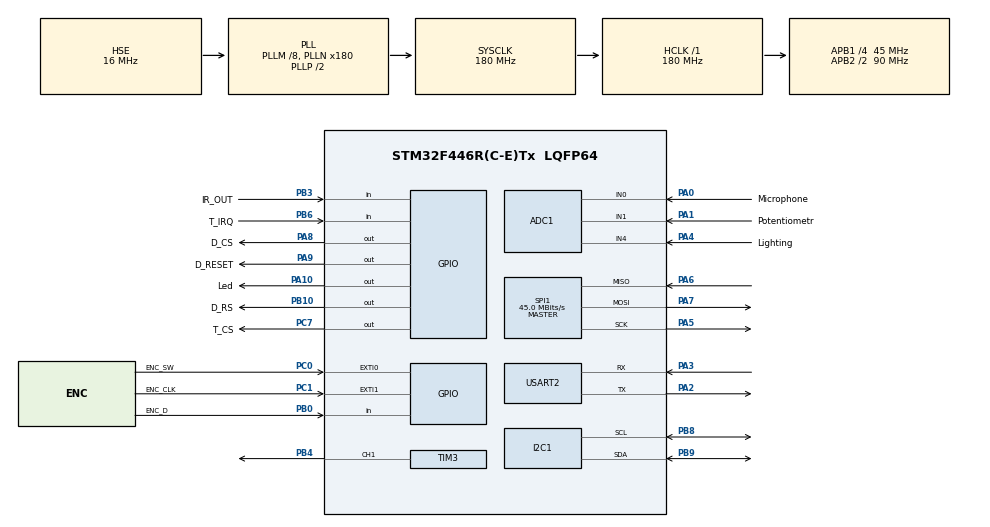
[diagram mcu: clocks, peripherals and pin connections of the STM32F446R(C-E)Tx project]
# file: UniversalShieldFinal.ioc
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ADC1.Channel-0\#ChannelRegularConversion=ADC_CHANNEL_0
ADC1.NbrOfConversionFlag=1
ADC1.Rank-0\#ChannelRegularConversion=1
ADC1.SamplingTime-0\#ChannelRegularConversion=ADC_SAMPLETIME_3CYCLES
ADC1.master=1
I2C1.I2C_Mode=I2C_Fast
Mcu.Family=STM32F4
Mcu.Name=STM32F446R(C-E)Tx
Mcu.Package=LQFP64
NVIC.EXTI0_IRQn=true\:15\:0\:true\:false\:true\:true\:true
NVIC.EXTI1_IRQn=true\:15\:0\:true\:false\:true\:true\:true
NVIC.PriorityGroup=NVIC_PRIORITYGROUP_4
PA0-WKUP.GPIO_Label=Microphone
PA0-WKUP.Signal=ADCx_IN0
PA1.GPIO_Label=Potentiometr
PA1.Signal=ADCx_IN1
PA10.GPIO_Label=Led
PA10.Signal=GPIO_Output
PA13.Mode=Serial_Wire
PA13.Signal=SYS_JTMS-SWDIO
PA14.Mode=Serial_Wire
PA14.Signal=SYS_JTCK-SWCLK
PA2.Mode=Asynchronous
PA2.Signal=USART2_TX
PA3.Mode=Asynchronous
PA3.Signal=USART2_RX
PA4.GPIO_Label=Lighting
PA4.Signal=ADCx_IN4
PA5.Mode=Full_Duplex_Master
PA5.Signal=SPI1_SCK
PA6.Mode=Full_Duplex_Master
PA6.Signal=SPI1_MISO
PA7.Mode=Full_Duplex_Master
PA7.Signal=SPI1_MOSI
PA8.GPIO_Label=D_CS
PA8.GPIO_Speed=GPIO_SPEED_FREQ_VERY_HIGH
PA8.PinState=GPIO_PIN_SET
PA8.Signal=GPIO_Output
PA9.GPIO_Label=D_RESET
PA9.GPIO_Speed=GPIO_SPEED_FREQ_VERY_HIGH
PA9.Signal=GPIO_Output
PB0.GPIO_Label=ENC_D
PB0.GPIO_PuPd=GPIO_PULLUP
PB0.Signal=GPIO_Input
PB10.GPIO_Label=D_RS
PB10.GPIO_Speed=GPIO_SPEED_FREQ_VERY_HIGH
PB10.Signal=GPIO_Output
PB3.GPIO_Label=IR_OUT
PB3.Signal=GPIO_Input
PB4.Signal=S_TIM3_CH1
PB6.GPIO_Label=T_IRQ
PB6.GPIO_PuPd=GPIO_PULLUP
PB6.Signal=GPIO_Input
PB8.Mode=I2C
PB8.Signal=I2C1_SCL
PB9.Mode=I2C
PB9.Signal=I2C1_SDA
PC0.GPIO_Label=ENC_SW
PC0.GPIO_ModeDefaultEXTI=GPIO_MODE_IT_FALLING
PC0.GPIO_PuPd=GPIO_PULLUP
PC0.Signal=GPXTI0
PC1.GPIO_Label=ENC_CLK
PC1.GPIO_ModeDefaultEXTI=GPIO_MODE_IT_FALLING
PC1.GPIO_PuPd=GPIO_PULLUP
PC1.Signal=GPXTI1
PC7.GPIO_Label=T_CS
PC7.GPIO_Speed=GPIO_SPEED_FREQ_VERY_HIGH
PC7.PinState=GPIO_PIN_SET
PC7.Signal=GPIO_Output
PH0-OSC_IN.Mode=HSE-External-Oscillator
PH0-OSC_IN.Signal=RCC_OSC_IN
PH1-OSC_OUT.Mode=HSE-External-Oscillator
PH1-OSC_OUT.Signal=RCC_OSC_OUT
ProjectManager.HeapSize=0x400
ProjectManager.StackSize=0x800
ProjectManager.TargetToolchain=STM32CubeIDE
RCC.AHBFreq_Value=180000000
RCC.APB1CLKDivider=RCC_HCLK_DIV4
RCC.APB1Freq_Value=45000000
RCC.APB1TimFreq_Value=90000000
RCC.APB2CLKDivider=RCC_HCLK_DIV2
RCC.APB2Freq_Value=90000000
RCC.APB2TimFreq_Value=180000000
RCC.CortexFreq_Value=180000000
RCC.HCLKFreq_Value=180000000
RCC.HSE_VALUE=16000000
RCC.PLLM=8
RCC.PLLN=180
RCC.PLLSourceVirtual=RCC_PLLSOURCE_HSE
RCC.SYSCLKFreq_VALUE=180000000
RCC.SYSCLKSource=RCC_SYSCLKSOURCE_PLLCLK
RCC.USBFreq_Value=180000000
RCC.VCOOutputFreq_Value=360000000
SH.ADCx_IN0.0=ADC1_IN0,IN0
SH.ADCx_IN1.0=ADC1_IN1,IN1
SH.ADCx_IN4.0=ADC1_IN4,IN4
SH.S_TIM3_CH1.0=TIM3_CH1,PWM Generation1 CH1
SPI1.CalculateBaudRate=45.0 MBits/s
SPI1.DataSize=SPI_DATASIZE_16BIT
SPI1.Direction=SPI_DIRECTION_2LINES
SPI1.Mode=SPI_MODE_MASTER
SPI1.VirtualType=VM_MASTER
TIM3.Channel-PWM\ Generation1\ CH1=TIM_CHANNEL_1
USART2.VirtualMode=VM_ASYNC
VP_TIM3_VS_ClockSourceINT.Mode=Internal
board=custom

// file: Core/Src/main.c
/* USER CODE BEGIN Header */
/**
  ******************************************************************************
  * @file           : main.c
  * @brief          : Main program body
  ******************************************************************************
  * @attention
  *
  * <h2><center>&copy; Copyright (c) 2020 STMicroelectronics.
  * All rights reserved.</center></h2>
  *
  * This software component is licensed by ST under BSD 3-Clause license,
  * the "License"; You may not use this file except in compliance with the
  * License. You may obtain a copy of the License at:
  *                        opensource.org/licenses/BSD-3-Clause
  *
  ******************************************************************************
  */
/* USER CODE END Header */

#include "main.h"
#include "adc.h"
#include "i2c.h"
#include "spi.h"
#include "tim.h"
#include "usart.h"
#include "gpio.h"

/* USER CODE BEGIN Includes */
#include "UniversalShield.h"
/* USER CODE END Includes */

void SystemClock_Config(void);

int main(void)
{

  /* MCU Configuration--------------------------------------------------------*/

  /* Reset of all peripherals, Initializes the Flash interface and the Systick. */
  HAL_Init();

  /* Configure the system clock */
  SystemClock_Config();

  /* Initialize all configured peripherals */
  MX_GPIO_Init();
  MX_ADC1_Init();
  MX_USART2_UART_Init();
  MX_I2C1_Init();
  MX_SPI1_Init();
  MX_TIM3_Init();
  /* USER CODE BEGIN 2 */
	//Вызов главной функции
	US_main();
  /* USER CODE END 2 */

  /* Infinite loop */
  while (1)
  {

  }
}

void SystemClock_Config(void)
{
  RCC_OscInitTypeDef RCC_OscInitStruct = {0};
  RCC_ClkInitTypeDef RCC_ClkInitStruct = {0};

  /** Configure the main internal regulator output voltage
  */
  __HAL_RCC_PWR_CLK_ENABLE();
  __HAL_PWR_VOLTAGESCALING_CONFIG(PWR_REGULATOR_VOLTAGE_SCALE1);
  /** Initializes the CPU, AHB and APB busses clocks
  */
  RCC_OscInitStruct.OscillatorType = RCC_OSCILLATORTYPE_HSE;
  RCC_OscInitStruct.HSEState = RCC_HSE_ON;
  RCC_OscInitStruct.PLL.PLLState = RCC_PLL_ON;
  RCC_OscInitStruct.PLL.PLLSource = RCC_PLLSOURCE_HSE;
  RCC_OscInitStruct.PLL.PLLM = 8;
  RCC_OscInitStruct.PLL.PLLN = 180;
  RCC_OscInitStruct.PLL.PLLP = RCC_PLLP_DIV2;
  RCC_OscInitStruct.PLL.PLLQ = 2;
  RCC_OscInitStruct.PLL.PLLR = 2;
  if (HAL_RCC_OscConfig(&RCC_OscInitStruct) != HAL_OK)
  {
    Error_Handler();
  }
  /** Activate the Over-Drive mode
  */
  if (HAL_PWREx_EnableOverDrive() != HAL_OK)
  {
    Error_Handler();
  }
  /** Initializes the CPU, AHB and APB busses clocks
  */
  RCC_ClkInitStruct.ClockType = RCC_CLOCKTYPE_HCLK|RCC_CLOCKTYPE_SYSCLK
                              |RCC_CLOCKTYPE_PCLK1|RCC_CLOCKTYPE_PCLK2;
  RCC_ClkInitStruct.SYSCLKSource = RCC_SYSCLKSOURCE_PLLCLK;
  RCC_ClkInitStruct.AHBCLKDivider = RCC_SYSCLK_DIV1;
  RCC_ClkInitStruct.APB1CLKDivider = RCC_HCLK_DIV4;
  RCC_ClkInitStruct.APB2CLKDivider = RCC_HCLK_DIV2;

  if (HAL_RCC_ClockConfig(&RCC_ClkInitStruct, FLASH_LATENCY_5) != HAL_OK)
  {
    Error_Handler();
  }
}

void Error_Handler(void)
{
}

/************************ (C) COPYRIGHT STMicroelectronics *****END OF FILE****/
